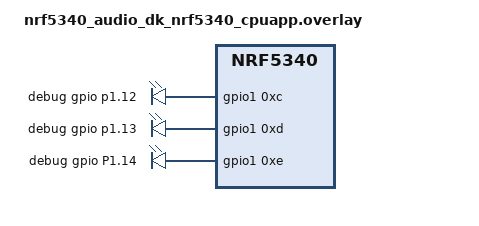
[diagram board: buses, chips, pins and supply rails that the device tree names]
/ {
    gpio_custom {
        compatible = "gpio-leds";
        debug01: dbg01 {
            gpios = < &gpio1 0xc 0 >;
            label = "debug gpio p1.12";
        };
        debug02: dbg02 {
            gpios = < &gpio1 0xd 0 >;
            label = "debug gpio p1.13";
        };
        debug03: dbg03 {
            gpios = < &gpio1 0xe 0 >;
            label = "debug gpio P1.14";
        };
    };
    aliases {
        debug01 = &debug01;
        debug02 = &debug02;
    };
};

// &leds{
//     led_9 {
//         gpios = < &gpio1 0x1 0xc >;
//         label = "dbg_p1.12 LED_MONO_PINK";
//     };
// };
